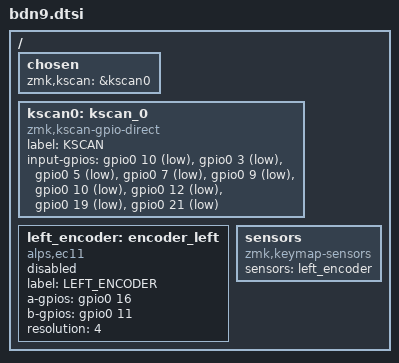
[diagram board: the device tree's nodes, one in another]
#include <dt-bindings/zmk/matrix-transform.h>

/ {
	chosen {
		zmk,kscan = &kscan0;
	};
	kscan0: kscan_0 {
		compatible = "zmk,kscan-gpio-direct";

		label = "KSCAN";

		input-gpios
			= <&gpio0 10 (GPIO_ACTIVE_LOW | GPIO_PULL_UP)>
			, <&gpio0 3 (GPIO_ACTIVE_LOW | GPIO_PULL_UP)>
			, <&gpio0 5 (GPIO_ACTIVE_LOW | GPIO_PULL_UP)>
			, <&gpio0 7 (GPIO_ACTIVE_LOW | GPIO_PULL_UP)>
			, <&gpio0 9 (GPIO_ACTIVE_LOW | GPIO_PULL_UP)>
			, <&gpio0 10 (GPIO_ACTIVE_LOW | GPIO_PULL_UP)>
			, <&gpio0 12 (GPIO_ACTIVE_LOW | GPIO_PULL_UP)>
			, <&gpio0 19 (GPIO_ACTIVE_LOW | GPIO_PULL_UP)>
			, <&gpio0 21 (GPIO_ACTIVE_LOW | GPIO_PULL_UP)>
			;
	};

	left_encoder: encoder_left {
		compatible = "alps,ec11";
		label = "LEFT_ENCODER";
		a-gpios = <&gpio0 16 (GPIO_ACTIVE_HIGH | GPIO_PULL_UP)>;
		b-gpios = <&gpio0 11 (GPIO_ACTIVE_HIGH | GPIO_PULL_UP)>;
		resolution = <4>;
		status = "enabled";
	};

	sensors {
		compatible = "zmk,keymap-sensors";
		sensors = <&left_encoder>;
	};
};

